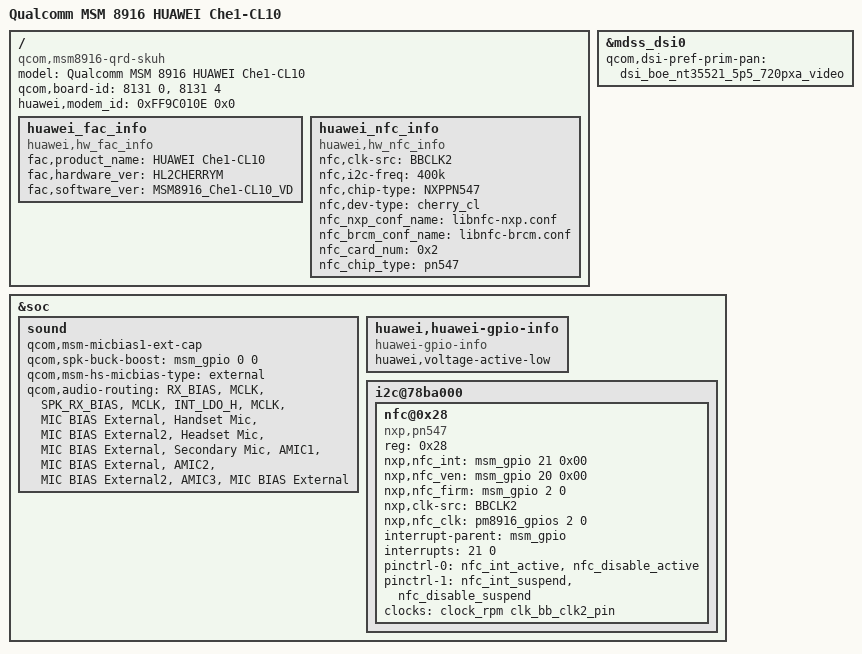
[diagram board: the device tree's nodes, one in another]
/* Copyright (c) 2014, The Linux Foundation. All rights reserved.
 *
 * This program is free software; you can redistribute it and/or modify
 * it under the terms of the GNU General Public License version 2 and
 * only version 2 as published by the Free Software Foundation.
 *
 * This program is distributed in the hope that it will be useful,
 * but WITHOUT ANY WARRANTY; without even the implied warranty of
 * MERCHANTABILITY or FITNESS FOR A PARTICULAR PURPOSE.  See the
 * GNU General Public License for more details.
 */

/dts-v1/;

#include "msm8916-qrd.dtsi"
#include "msm8916-memory.dtsi"
#include "cherry/msm8916-qrd-cherry.dtsi"
 
/ {
	model = "Qualcomm MSM 8916 HUAWEI Che1-CL10";
	compatible = "qcom,msm8916-qrd-skuh", "qcom,msm8916-qrd", "qcom,msm8916", "qcom,qrd";
	qcom,board-id = <8131 0>, <8131 4>;
	huawei,modem_id = <0xFF9C010E 0x0>;
};

&mdss_dsi0 {
	qcom,dsi-pref-prim-pan = <&dsi_boe_nt35521_5p5_720pxa_video>;
	
};

&soc {
	sound {
		qcom,msm-micbias1-ext-cap;
        	qcom,spk-buck-boost = <&msm_gpio 0 0>;
		qcom,msm-hs-micbias-type = "external";
		qcom,audio-routing =
				"RX_BIAS", "MCLK",
				"SPK_RX_BIAS", "MCLK",
				"INT_LDO_H", "MCLK",
				"MIC BIAS External", "Handset Mic",
				"MIC BIAS External2", "Headset Mic",
				"MIC BIAS External", "Secondary Mic",
				"AMIC1", "MIC BIAS External",
				"AMIC2", "MIC BIAS External2",
				"AMIC3", "MIC BIAS External";
	};

	huawei,huawei-gpio-info {
		compatible = "huawei-gpio-info";
		huawei,voltage-active-low;
	};

	i2c@78ba000 { /* BLSP1 QUP6 */
		nfc@0x28 {
			compatible = "nxp,pn547";
			status = "ok";
			reg = <0x28>;
			nxp,nfc_int = <&msm_gpio 21 0x00>;
			nxp,nfc_ven = <&msm_gpio 20 0x00>;
			nxp,nfc_firm = <&msm_gpio 2 0>;
			nxp,clk-src = "BBCLK2";
			nxp,nfc_clk = <&pm8916_gpios 2 0>;
			interrupt-parent = <&msm_gpio>;
			interrupts = <21 0>; /*1 = low-to-high edge triggered
                                                 2 = high-to-low edge triggered
                                                 4 = active high level-sensitive
                                                 8 = active low level-sensitive */
			interrupt-names = "nfc_irq";
			pinctrl-names = "nfc_active","nfc_suspend";
			pinctrl-0 = <&nfc_int_active &nfc_disable_active>;
			pinctrl-1 = <&nfc_int_suspend &nfc_disable_suspend>;
			clocks = <&clock_rpm clk_bb_clk2_pin>;
			clock-names = "pn547_clk";
		};
	};
};

/ {
	huawei_fac_info {
			  compatible = "huawei,hw_fac_info";
			  fac,product_name = "HUAWEI Che1-CL10";
			  fac,hardware_ver = "HL2CHERRYM";
			  fac,software_ver = "MSM8916_Che1-CL10_VD";
			  status = "ok";
	};

	huawei_nfc_info {
		compatible = "huawei,hw_nfc_info";
		nfc,clk-src = "BBCLK2";
		nfc,i2c-freq = "400k";
		nfc,chip-type = "NXPPN547";
		nfc,dev-type = "cherry_cl";
		nfc_nxp_conf_name = "libnfc-nxp.conf";
		nfc_brcm_conf_name = "libnfc-brcm.conf";
		nfc_card_num = <0x2>;
		nfc_chip_type = "pn547";
		status = "ok";
	};
};
